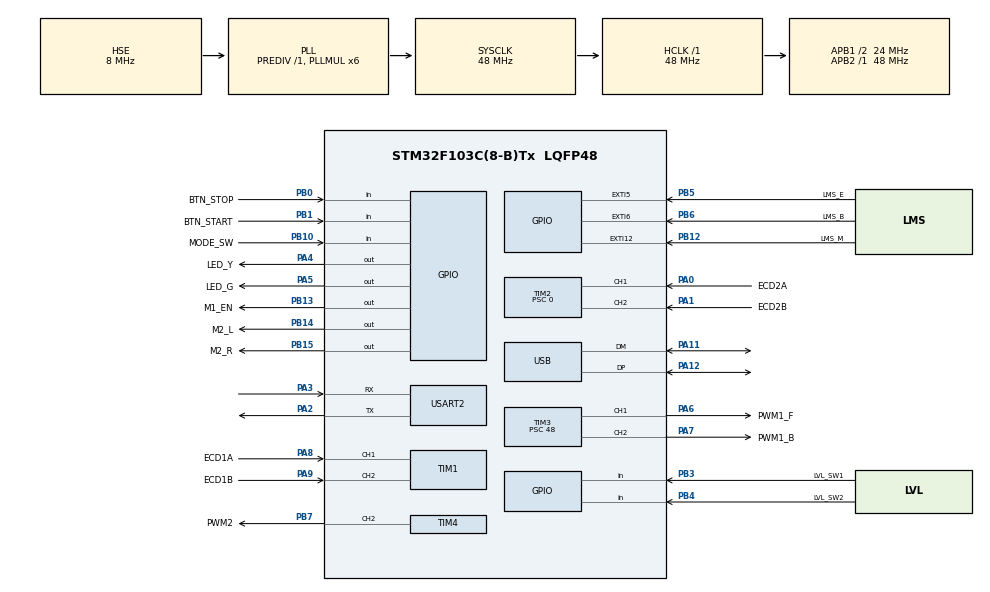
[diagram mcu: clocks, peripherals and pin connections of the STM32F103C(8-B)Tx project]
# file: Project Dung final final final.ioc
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Mcu.Family=STM32F1
Mcu.Name=STM32F103C(8-B)Tx
Mcu.Package=LQFP48
NVIC.EXTI15_10_IRQn=true\:2\:0\:true\:false\:true\:true\:true\:true
NVIC.EXTI9_5_IRQn=true\:2\:0\:true\:false\:true\:true\:true\:true
NVIC.PriorityGroup=NVIC_PRIORITYGROUP_4
NVIC.TIM4_IRQn=true\:1\:0\:true\:false\:true\:true\:true\:true
NVIC.USB_LP_CAN1_RX0_IRQn=true\:0\:0\:false\:false\:true\:false\:true\:true
PA0-WKUP.GPIO_Label=ECD2A
PA0-WKUP.Signal=S_TIM2_CH1_ETR
PA1.GPIO_Label=ECD2B
PA1.Signal=S_TIM2_CH2
PA11.Mode=Device
PA11.Signal=USB_DM
PA12.Mode=Device
PA12.Signal=USB_DP
PA13.Mode=Serial_Wire
PA13.Signal=SYS_JTMS-SWDIO
PA14.Mode=Serial_Wire
PA14.Signal=SYS_JTCK-SWCLK
PA2.Mode=Asynchronous
PA2.Signal=USART2_TX
PA3.Mode=Asynchronous
PA3.Signal=USART2_RX
PA4.GPIO_Label=LED_Y
PA4.Signal=GPIO_Output
PA5.GPIO_Label=LED_G
PA5.Signal=GPIO_Output
PA6.GPIO_Label=PWM1_F
PA6.Signal=S_TIM3_CH1
PA7.GPIO_Label=PWM1_B
PA7.Signal=S_TIM3_CH2
PA8.GPIO_Label=ECD1A
PA8.Signal=S_TIM1_CH1
PA9.GPIO_Label=ECD1B
PA9.Signal=S_TIM1_CH2
PB0.GPIO_Label=BTN_STOP
PB0.GPIO_PuPd=GPIO_PULLUP
PB0.Signal=GPIO_Input
PB1.GPIO_Label=BTN_START
PB1.GPIO_PuPd=GPIO_PULLUP
PB1.Signal=GPIO_Input
PB10.GPIO_Label=MODE_SW
PB10.GPIO_PuPd=GPIO_PULLUP
PB10.Signal=GPIO_Input
PB12.GPIO_Label=LMS_M
PB12.GPIO_ModeDefaultEXTI=GPIO_MODE_IT_RISING_FALLING
PB12.GPIO_PuPd=GPIO_PULLUP
PB12.Signal=GPXTI12
PB13.GPIO_Label=M1_EN
PB13.Signal=GPIO_Output
PB14.GPIO_Label=M2_L
PB14.Signal=GPIO_Output
PB15.GPIO_Label=M2_R
PB15.Signal=GPIO_Output
PB3.GPIO_Label=LVL_SW1
PB3.GPIO_PuPd=GPIO_PULLUP
PB3.Signal=GPIO_Input
PB4.GPIO_Label=LVL_SW2
PB4.GPIO_PuPd=GPIO_PULLUP
PB4.Signal=GPIO_Input
PB5.GPIO_Label=LMS_E
PB5.GPIO_ModeDefaultEXTI=GPIO_MODE_IT_RISING_FALLING
PB5.GPIO_PuPd=GPIO_NOPULL
PB5.Signal=GPXTI5
PB6.GPIO_Label=LMS_B
PB6.GPIO_ModeDefaultEXTI=GPIO_MODE_IT_RISING_FALLING
PB6.GPIO_PuPd=GPIO_NOPULL
PB6.Signal=GPXTI6
PB7.GPIO_Label=PWM2
PB7.Signal=S_TIM4_CH2
PD0-OSC_IN.GPIO_Label=OSC1
PD0-OSC_IN.Mode=HSE-External-Oscillator
PD0-OSC_IN.Signal=RCC_OSC_IN
PD1-OSC_OUT.GPIO_Label=OSC2
PD1-OSC_OUT.Mode=HSE-External-Oscillator
PD1-OSC_OUT.Signal=RCC_OSC_OUT
ProjectManager.HeapSize=0x200
ProjectManager.StackSize=0x400
ProjectManager.TargetToolchain=STM32CubeIDE
RCC.ADCPresc=RCC_ADCPCLK2_DIV4
RCC.AHBFreq_Value=48000000
RCC.APB1CLKDivider=RCC_HCLK_DIV2
RCC.APB1Freq_Value=24000000
RCC.APB1TimFreq_Value=48000000
RCC.APB2Freq_Value=48000000
RCC.APB2TimFreq_Value=48000000
RCC.HCLKFreq_Value=48000000
RCC.PLLMUL=RCC_PLL_MUL6
RCC.SYSCLKFreq_VALUE=48000000
RCC.SYSCLKSource=RCC_SYSCLKSOURCE_PLLCLK
RCC.USBFreq_Value=48000000
SH.S_TIM1_CH1.0=TIM1_CH1,Encoder_Interface
SH.S_TIM1_CH2.0=TIM1_CH2,Encoder_Interface
SH.S_TIM2_CH1_ETR.0=TIM2_CH1,Encoder_Interface
SH.S_TIM2_CH2.0=TIM2_CH2,Encoder_Interface
SH.S_TIM3_CH1.0=TIM3_CH1,PWM Generation1 CH1
SH.S_TIM3_CH2.0=TIM3_CH2,PWM Generation2 CH2
SH.S_TIM4_CH2.0=TIM4_CH2,PWM Generation2 CH2
TIM1.AutoReloadPreload=TIM_AUTORELOAD_PRELOAD_ENABLE
TIM1.EncoderMode=TIM_ENCODERMODE_TI12
TIM1.IC1Filter=10
TIM1.IC2Filter=10
TIM2.AutoReloadPreload=TIM_AUTORELOAD_PRELOAD_ENABLE
TIM2.EncoderMode=TIM_ENCODERMODE_TI12
TIM2.IC1Filter=0
TIM2.IC2Filter=0
TIM2.Period=65535
TIM2.Prescaler=0
TIM3.AutoReloadPreload=TIM_AUTORELOAD_PRELOAD_ENABLE
TIM3.Channel-PWM\ Generation1\ CH1=TIM_CHANNEL_1
TIM3.Channel-PWM\ Generation2\ CH2=TIM_CHANNEL_2
TIM3.Period=499
TIM3.Prescaler=48
TIM4.AutoReloadPreload=TIM_AUTORELOAD_PRELOAD_ENABLE
TIM4.Channel-PWM\ Generation2\ CH2=TIM_CHANNEL_2
TIM4.Period=999
TIM4.Prescaler=48
USART2.VirtualMode=VM_ASYNC
USB_DEVICE.APP_RX_DATA_SIZE=64
USB_DEVICE.APP_TX_DATA_SIZE=64
USB_DEVICE.CLASS_NAME_FS=CDC
USB_DEVICE.VirtualMode=Cdc
USB_DEVICE.VirtualModeFS=Cdc_FS
VP_USB_DEVICE_VS_USB_DEVICE_CDC_FS.Mode=CDC_FS
board=custom

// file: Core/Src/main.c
/* USER CODE BEGIN Header */
/**
 ******************************************************************************
 * @file           : main.c (FINAL x3)
 * @brief          : Main program body
 ******************************************************************************
 * @attention
 *
 * Copyright (c) 2022 STMicroelectronics.
 * All rights reserved.
 *
 * This software is licensed under terms that can be found in the LICENSE file
 * in the root directory of this software component.
 * If no LICENSE file comes with this software, it is provided AS-IS.
 *
 ******************************************************************************
 */
/* USER CODE END Header */
#include "main.h"
#include "usb_device.h"

/* USER CODE BEGIN Includes */
#include <stdbool.h>
#include "user_func.h"
/* USER CODE END Includes */

TIM_HandleTypeDef htim1;
TIM_HandleTypeDef htim2;
TIM_HandleTypeDef htim3;
TIM_HandleTypeDef htim4;

UART_HandleTypeDef huart2;

void SystemClock_Config(void);
static void MX_GPIO_Init(void);
static void MX_TIM1_Init(void);
static void MX_TIM2_Init(void);
static void MX_TIM3_Init(void);
static void MX_TIM4_Init(void);
static void MX_USART2_UART_Init(void);

/* USER CODE BEGIN 0 */
bool END_REACH = 0, BEGIN_REACH = 0, MID_REACH = 0;
Button BTN_Start, BTN_Stop, SW_Mode, SW_Lvl1, SW_Lvl2;

State_t state;
/* USER CODE END 0 */

int main(void)
{

  /* MCU Configuration--------------------------------------------------------*/

  /* Reset of all peripherals, Initializes the Flash interface and the Systick. */
  HAL_Init();

  /* Configure the system clock */
  SystemClock_Config();

  /* Initialize all configured peripherals */
  MX_GPIO_Init();
  MX_TIM1_Init();
  MX_TIM2_Init();
  MX_TIM3_Init();
  MX_TIM4_Init();
  MX_USB_DEVICE_Init();
  MX_USART2_UART_Init();
  /* USER CODE BEGIN 2 */
  start_up();
  /* USER CODE END 2 */

  /* Infinite loop */
  while (1) {

    /* USER CODE BEGIN 3 */
	state = buttonRead(&SW_Mode);
	if (SW_Mode.hasChanged) {
	  SW_Mode.hasChanged = false;
	  if (state == IDLE) {
		active_idle();
	  } else if (state == RUN) {
		active_run();
	  }
	}
	apply_state();
  }
  /* USER CODE END 3 */
}

void SystemClock_Config(void)
{
  RCC_OscInitTypeDef RCC_OscInitStruct = {0};
  RCC_ClkInitTypeDef RCC_ClkInitStruct = {0};
  RCC_PeriphCLKInitTypeDef PeriphClkInit = {0};

  /** Initializes the RCC Oscillators according to the specified parameters
  * in the RCC_OscInitTypeDef structure.
  */
  RCC_OscInitStruct.OscillatorType = RCC_OSCILLATORTYPE_HSE;
  RCC_OscInitStruct.HSEState = RCC_HSE_ON;
  RCC_OscInitStruct.HSEPredivValue = RCC_HSE_PREDIV_DIV1;
  RCC_OscInitStruct.HSIState = RCC_HSI_ON;
  RCC_OscInitStruct.PLL.PLLState = RCC_PLL_ON;
  RCC_OscInitStruct.PLL.PLLSource = RCC_PLLSOURCE_HSE;
  RCC_OscInitStruct.PLL.PLLMUL = RCC_PLL_MUL6;
  if (HAL_RCC_OscConfig(&RCC_OscInitStruct) != HAL_OK)
  {
    Error_Handler();
  }

  /** Initializes the CPU, AHB and APB buses clocks
  */
  RCC_ClkInitStruct.ClockType = RCC_CLOCKTYPE_HCLK|RCC_CLOCKTYPE_SYSCLK
                              |RCC_CLOCKTYPE_PCLK1|RCC_CLOCKTYPE_PCLK2;
  RCC_ClkInitStruct.SYSCLKSource = RCC_SYSCLKSOURCE_PLLCLK;
  RCC_ClkInitStruct.AHBCLKDivider = RCC_SYSCLK_DIV1;
  RCC_ClkInitStruct.APB1CLKDivider = RCC_HCLK_DIV2;
  RCC_ClkInitStruct.APB2CLKDivider = RCC_HCLK_DIV1;

  if (HAL_RCC_ClockConfig(&RCC_ClkInitStruct, FLASH_LATENCY_1) != HAL_OK)
  {
    Error_Handler();
  }
  PeriphClkInit.PeriphClockSelection = RCC_PERIPHCLK_USB;
  PeriphClkInit.UsbClockSelection = RCC_USBCLKSOURCE_PLL;
  if (HAL_RCCEx_PeriphCLKConfig(&PeriphClkInit) != HAL_OK)
  {
    Error_Handler();
  }
}

static void MX_TIM1_Init(void)
{

  TIM_Encoder_InitTypeDef sConfig = {0};
  TIM_MasterConfigTypeDef sMasterConfig = {0};

  htim1.Instance = TIM1;
  htim1.Init.Prescaler = 0;
  htim1.Init.CounterMode = TIM_COUNTERMODE_UP;
  htim1.Init.Period = 65535;
  htim1.Init.ClockDivision = TIM_CLOCKDIVISION_DIV1;
  htim1.Init.RepetitionCounter = 0;
  htim1.Init.AutoReloadPreload = TIM_AUTORELOAD_PRELOAD_ENABLE;
  sConfig.EncoderMode = TIM_ENCODERMODE_TI12;
  sConfig.IC1Polarity = TIM_ICPOLARITY_RISING;
  sConfig.IC1Selection = TIM_ICSELECTION_DIRECTTI;
  sConfig.IC1Prescaler = TIM_ICPSC_DIV1;
  sConfig.IC1Filter = 10;
  sConfig.IC2Polarity = TIM_ICPOLARITY_RISING;
  sConfig.IC2Selection = TIM_ICSELECTION_DIRECTTI;
  sConfig.IC2Prescaler = TIM_ICPSC_DIV1;
  sConfig.IC2Filter = 10;
  if (HAL_TIM_Encoder_Init(&htim1, &sConfig) != HAL_OK)
  {
    Error_Handler();
  }
  sMasterConfig.MasterOutputTrigger = TIM_TRGO_RESET;
  sMasterConfig.MasterSlaveMode = TIM_MASTERSLAVEMODE_DISABLE;
  if (HAL_TIMEx_MasterConfigSynchronization(&htim1, &sMasterConfig) != HAL_OK)
  {
    Error_Handler();
  }

}

static void MX_TIM2_Init(void)
{

  TIM_Encoder_InitTypeDef sConfig = {0};
  TIM_MasterConfigTypeDef sMasterConfig = {0};

  htim2.Instance = TIM2;
  htim2.Init.Prescaler = 0;
  htim2.Init.CounterMode = TIM_COUNTERMODE_UP;
  htim2.Init.Period = 65535;
  htim2.Init.ClockDivision = TIM_CLOCKDIVISION_DIV1;
  htim2.Init.AutoReloadPreload = TIM_AUTORELOAD_PRELOAD_ENABLE;
  sConfig.EncoderMode = TIM_ENCODERMODE_TI12;
  sConfig.IC1Polarity = TIM_ICPOLARITY_RISING;
  sConfig.IC1Selection = TIM_ICSELECTION_DIRECTTI;
  sConfig.IC1Prescaler = TIM_ICPSC_DIV1;
  sConfig.IC1Filter = 0;
  sConfig.IC2Polarity = TIM_ICPOLARITY_RISING;
  sConfig.IC2Selection = TIM_ICSELECTION_DIRECTTI;
  sConfig.IC2Prescaler = TIM_ICPSC_DIV1;
  sConfig.IC2Filter = 0;
  if (HAL_TIM_Encoder_Init(&htim2, &sConfig) != HAL_OK)
  {
    Error_Handler();
  }
  sMasterConfig.MasterOutputTrigger = TIM_TRGO_RESET;
  sMasterConfig.MasterSlaveMode = TIM_MASTERSLAVEMODE_DISABLE;
  if (HAL_TIMEx_MasterConfigSynchronization(&htim2, &sMasterConfig) != HAL_OK)
  {
    Error_Handler();
  }

}

static void MX_TIM3_Init(void)
{

  TIM_MasterConfigTypeDef sMasterConfig = {0};
  TIM_OC_InitTypeDef sConfigOC = {0};

  htim3.Instance = TIM3;
  htim3.Init.Prescaler = 48;
  htim3.Init.CounterMode = TIM_COUNTERMODE_UP;
  htim3.Init.Period = 499;
  htim3.Init.ClockDivision = TIM_CLOCKDIVISION_DIV1;
  htim3.Init.AutoReloadPreload = TIM_AUTORELOAD_PRELOAD_ENABLE;
  if (HAL_TIM_PWM_Init(&htim3) != HAL_OK)
  {
    Error_Handler();
  }
  sMasterConfig.MasterOutputTrigger = TIM_TRGO_RESET;
  sMasterConfig.MasterSlaveMode = TIM_MASTERSLAVEMODE_DISABLE;
  if (HAL_TIMEx_MasterConfigSynchronization(&htim3, &sMasterConfig) != HAL_OK)
  {
    Error_Handler();
  }
  sConfigOC.OCMode = TIM_OCMODE_PWM1;
  sConfigOC.Pulse = 0;
  sConfigOC.OCPolarity = TIM_OCPOLARITY_HIGH;
  sConfigOC.OCFastMode = TIM_OCFAST_DISABLE;
  if (HAL_TIM_PWM_ConfigChannel(&htim3, &sConfigOC, TIM_CHANNEL_1) != HAL_OK)
  {
    Error_Handler();
  }
  if (HAL_TIM_PWM_ConfigChannel(&htim3, &sConfigOC, TIM_CHANNEL_2) != HAL_OK)
  {
    Error_Handler();
  }
  HAL_TIM_MspPostInit(&htim3);

}

static void MX_TIM4_Init(void)
{

  TIM_MasterConfigTypeDef sMasterConfig = {0};
  TIM_OC_InitTypeDef sConfigOC = {0};

  htim4.Instance = TIM4;
  htim4.Init.Prescaler = 48;
  htim4.Init.CounterMode = TIM_COUNTERMODE_UP;
  htim4.Init.Period = 999;
  htim4.Init.ClockDivision = TIM_CLOCKDIVISION_DIV1;
  htim4.Init.AutoReloadPreload = TIM_AUTORELOAD_PRELOAD_ENABLE;
  if (HAL_TIM_PWM_Init(&htim4) != HAL_OK)
  {
    Error_Handler();
  }
  sMasterConfig.MasterOutputTrigger = TIM_TRGO_RESET;
  sMasterConfig.MasterSlaveMode = TIM_MASTERSLAVEMODE_DISABLE;
  if (HAL_TIMEx_MasterConfigSynchronization(&htim4, &sMasterConfig) != HAL_OK)
  {
    Error_Handler();
  }
  sConfigOC.OCMode = TIM_OCMODE_PWM1;
  sConfigOC.Pulse = 0;
  sConfigOC.OCPolarity = TIM_OCPOLARITY_HIGH;
  sConfigOC.OCFastMode = TIM_OCFAST_DISABLE;
  if (HAL_TIM_PWM_ConfigChannel(&htim4, &sConfigOC, TIM_CHANNEL_2) != HAL_OK)
  {
    Error_Handler();
  }
  HAL_TIM_MspPostInit(&htim4);

}

static void MX_USART2_UART_Init(void)
{

  huart2.Instance = USART2;
  huart2.Init.BaudRate = 115200;
  huart2.Init.WordLength = UART_WORDLENGTH_8B;
  huart2.Init.StopBits = UART_STOPBITS_1;
  huart2.Init.Parity = UART_PARITY_NONE;
  huart2.Init.Mode = UART_MODE_TX_RX;
  huart2.Init.HwFlowCtl = UART_HWCONTROL_NONE;
  huart2.Init.OverSampling = UART_OVERSAMPLING_16;
  if (HAL_UART_Init(&huart2) != HAL_OK)
  {
    Error_Handler();
  }

}

static void MX_GPIO_Init(void)
{
  GPIO_InitTypeDef GPIO_InitStruct = {0};

  /* GPIO Ports Clock Enable */
  __HAL_RCC_GPIOC_CLK_ENABLE();
  __HAL_RCC_GPIOD_CLK_ENABLE();
  __HAL_RCC_GPIOA_CLK_ENABLE();
  __HAL_RCC_GPIOB_CLK_ENABLE();

  /*Configure GPIO pin Output Level */
  HAL_GPIO_WritePin(GPIOA, LED_Y_Pin|LED_G_Pin, GPIO_PIN_RESET);

  /*Configure GPIO pin Output Level */
  HAL_GPIO_WritePin(GPIOB, M1_EN_Pin|M2_L_Pin|M2_R_Pin, GPIO_PIN_RESET);

  /*Configure GPIO pins : PC13 PC14 PC15 */
  GPIO_InitStruct.Pin = GPIO_PIN_13|GPIO_PIN_14|GPIO_PIN_15;
  GPIO_InitStruct.Mode = GPIO_MODE_ANALOG;
  HAL_GPIO_Init(GPIOC, &GPIO_InitStruct);

  /*Configure GPIO pins : LED_Y_Pin LED_G_Pin */
  GPIO_InitStruct.Pin = LED_Y_Pin|LED_G_Pin;
  GPIO_InitStruct.Mode = GPIO_MODE_OUTPUT_PP;
  GPIO_InitStruct.Pull = GPIO_NOPULL;
  GPIO_InitStruct.Speed = GPIO_SPEED_FREQ_LOW;
  HAL_GPIO_Init(GPIOA, &GPIO_InitStruct);

  /*Configure GPIO pins : BTN_STOP_Pin BTN_START_Pin MODE_SW_Pin LVL_SW1_Pin
                           LVL_SW2_Pin */
  GPIO_InitStruct.Pin = BTN_STOP_Pin|BTN_START_Pin|MODE_SW_Pin|LVL_SW1_Pin
                          |LVL_SW2_Pin;
  GPIO_InitStruct.Mode = GPIO_MODE_INPUT;
  GPIO_InitStruct.Pull = GPIO_PULLUP;
  HAL_GPIO_Init(GPIOB, &GPIO_InitStruct);

  /*Configure GPIO pins : PB2 PB11 PB8 PB9 */
  GPIO_InitStruct.Pin = GPIO_PIN_2|GPIO_PIN_11|GPIO_PIN_8|GPIO_PIN_9;
  GPIO_InitStruct.Mode = GPIO_MODE_ANALOG;
  HAL_GPIO_Init(GPIOB, &GPIO_InitStruct);

  /*Configure GPIO pin : LMS_M_Pin */
  GPIO_InitStruct.Pin = LMS_M_Pin;
  GPIO_InitStruct.Mode = GPIO_MODE_IT_RISING_FALLING;
  GPIO_InitStruct.Pull = GPIO_PULLUP;
  HAL_GPIO_Init(LMS_M_GPIO_Port, &GPIO_InitStruct);

  /*Configure GPIO pins : M1_EN_Pin M2_L_Pin M2_R_Pin */
  GPIO_InitStruct.Pin = M1_EN_Pin|M2_L_Pin|M2_R_Pin;
  GPIO_InitStruct.Mode = GPIO_MODE_OUTPUT_PP;
  GPIO_InitStruct.Pull = GPIO_NOPULL;
  GPIO_InitStruct.Speed = GPIO_SPEED_FREQ_LOW;
  HAL_GPIO_Init(GPIOB, &GPIO_InitStruct);

  /*Configure GPIO pins : PA10 PA15 */
  GPIO_InitStruct.Pin = GPIO_PIN_10|GPIO_PIN_15;
  GPIO_InitStruct.Mode = GPIO_MODE_ANALOG;
  HAL_GPIO_Init(GPIOA, &GPIO_InitStruct);

  /*Configure GPIO pins : LMS_E_Pin LMS_B_Pin */
  GPIO_InitStruct.Pin = LMS_E_Pin|LMS_B_Pin;
  GPIO_InitStruct.Mode = GPIO_MODE_IT_RISING_FALLING;
  GPIO_InitStruct.Pull = GPIO_NOPULL;
  HAL_GPIO_Init(GPIOB, &GPIO_InitStruct);

  /* EXTI interrupt init*/
  HAL_NVIC_SetPriority(EXTI9_5_IRQn, 2, 0);
  HAL_NVIC_EnableIRQ(EXTI9_5_IRQn);

  HAL_NVIC_SetPriority(EXTI15_10_IRQn, 2, 0);
  HAL_NVIC_EnableIRQ(EXTI15_10_IRQn);

}

void Error_Handler(void)
{
  __disable_irq();
  while (1) {
  }
}
